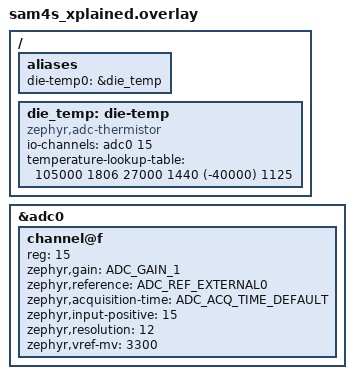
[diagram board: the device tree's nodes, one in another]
/*
 * SPDX-License-Identifier: Apache-2.0
 *
 * Copyright (c) 2023, Basalte bv
 */

#include <zephyr/dt-bindings/adc/adc.h>

/ {
	aliases {
		die-temp0 = &die_temp;
	};

	die_temp: die-temp {
		status = "okay";
		compatible = "zephyr,adc-thermistor";
		io-channels = <&adc0 15>;
		temperature-lookup-table = <
			105000   1806
			27000    1440
			(-40000) 1125
		>;
	};
};

&adc0 {
	status = "okay";
	#address-cells = <1>;
	#size-cells = <0>;

	/* Internal die temperature sensor */
	channel@f {
		reg = <15>;
		zephyr,gain = "ADC_GAIN_1";
		zephyr,reference = "ADC_REF_EXTERNAL0";
		zephyr,acquisition-time = <ADC_ACQ_TIME_DEFAULT>;
		zephyr,input-positive = <15>;
		zephyr,resolution = <12>;
		zephyr,vref-mv = <3300>;
	};
};
